VERSION ""

NS_ :

BS_:

BU_: MotorCtrl BMS Gateway DiagTool

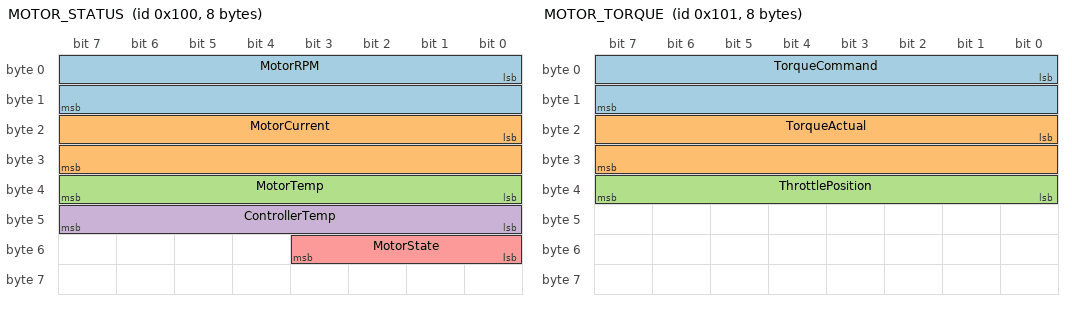
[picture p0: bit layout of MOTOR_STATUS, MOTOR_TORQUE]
BO_ 256 MOTOR_STATUS: 8 MotorCtrl
 SG_ MotorRPM : 0|16@1+ (1,0) [0|8000] "rpm" Gateway
 SG_ MotorCurrent : 16|16@1- (0.1,0) [-500|500] "A" Gateway
 SG_ MotorTemp : 32|8@1+ (1,-40) [-40|215] "degC" Gateway
 SG_ ControllerTemp : 40|8@1+ (1,-40) [-40|215] "degC" Gateway
 SG_ MotorState : 48|4@1+ (1,0) [0|15] "" Gateway

BO_ 257 MOTOR_TORQUE: 8 MotorCtrl
 SG_ TorqueCommand : 0|16@1- (0.1,0) [-1000|1000] "Nm" Gateway
 SG_ TorqueActual : 16|16@1- (0.1,0) [-1000|1000] "Nm" Gateway
 SG_ ThrottlePosition : 32|8@1+ (0.4,0) [0|100] "%" Gateway

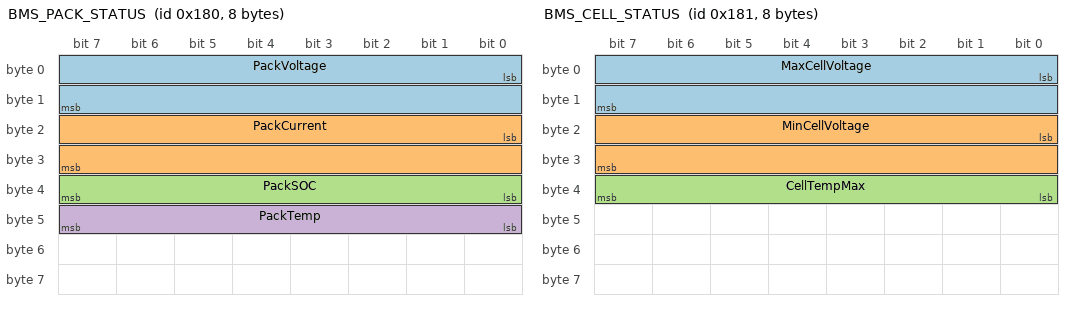
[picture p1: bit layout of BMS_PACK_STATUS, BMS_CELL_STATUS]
BO_ 384 BMS_PACK_STATUS: 8 BMS
 SG_ PackVoltage : 0|16@1+ (0.1,0) [0|500] "V" Gateway
 SG_ PackCurrent : 16|16@1- (0.1,0) [-300|300] "A" Gateway
 SG_ PackSOC : 32|8@1+ (0.5,0) [0|100] "%" Gateway
 SG_ PackTemp : 40|8@1+ (1,-40) [-40|215] "degC" Gateway

BO_ 385 BMS_CELL_STATUS: 8 BMS
 SG_ MaxCellVoltage : 0|16@1+ (0.001,0) [0|5] "V" Gateway
 SG_ MinCellVoltage : 16|16@1+ (0.001,0) [0|5] "V" Gateway
 SG_ CellTempMax : 32|8@1+ (1,-40) [-40|215] "degC" Gateway

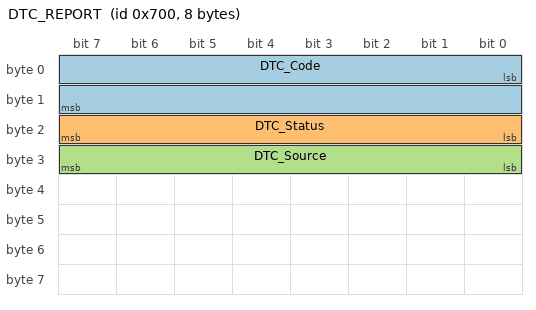
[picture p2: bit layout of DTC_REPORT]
BO_ 1792 DTC_REPORT: 8 DiagTool
 SG_ DTC_Code : 0|16@1+ (1,0) [0|65535] "" Gateway
 SG_ DTC_Status : 16|8@1+ (1,0) [0|255] "" Gateway
 SG_ DTC_Source : 24|8@1+ (1,0) [0|255] "" Gateway

CM_ BO_ 1792 "UDS-style DTC report frame, broadcast when a fault is set or cleared.";
CM_ SG_ 256 MotorState "0=Idle 1=Running 2=Regen 3=Fault 4=Derate";
CM_ SG_ 1792 DTC_Source "1=MotorCtrl 2=BMS 3=Gateway";

VAL_ 1792 DTC_Code 4361 "P0C73_MOTOR_OVERTEMP" 4362 "P0C74_MOTOR_OVERCURRENT" 4363 "P0AA6_BMS_CELL_UV" 4364 "P0AA7_BMS_CELL_OV" 4365 "P0C31_CONTROLLER_OVERTEMP" ;
VAL_ 1792 DTC_Status 1 "SET" 0 "CLEARED" ;
VAL_ 1792 DTC_Source 1 "MotorCtrl" 2 "BMS" 3 "Gateway" ;
VAL_ 256 MotorState 0 "Idle" 1 "Running" 2 "Regen" 3 "Fault" 4 "Derate" ;
